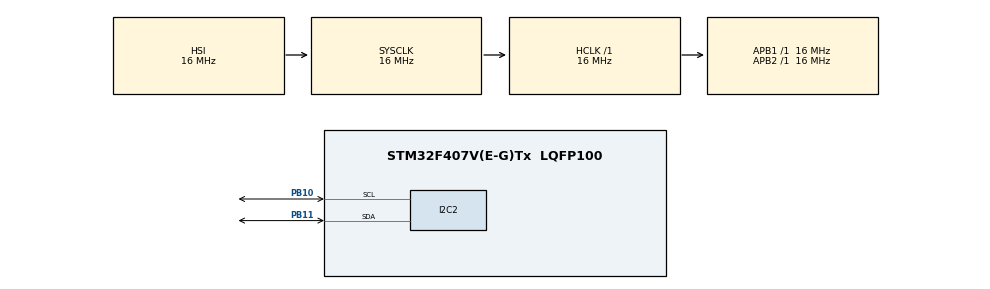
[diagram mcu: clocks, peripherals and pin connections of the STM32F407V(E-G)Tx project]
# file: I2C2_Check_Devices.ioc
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Mcu.Family=STM32F4
Mcu.Name=STM32F407V(E-G)Tx
Mcu.Package=LQFP100
NVIC.PriorityGroup=NVIC_PRIORITYGROUP_4
PB10.Mode=I2C
PB10.Signal=I2C2_SCL
PB11.Mode=I2C
PB11.Signal=I2C2_SDA
ProjectManager.HeapSize=0x200
ProjectManager.StackSize=0x400
ProjectManager.TargetToolchain=STM32CubeIDE
RCC.AHBFreq_Value=16000000
RCC.APB1Freq_Value=16000000
RCC.APB2Freq_Value=16000000
RCC.CortexFreq_Value=16000000
RCC.HSE_VALUE=25000000
RCC.HSI_VALUE=16000000
RCC.LSE_VALUE=32768
RCC.SYSCLKFreq_VALUE=16000000
RCC.VCOOutputFreq_Value=192000000
board=custom

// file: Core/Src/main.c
/* USER CODE BEGIN Header */
/**
 ******************************************************************************
 * @file           : main.c
 * @brief          : Main program body
 ******************************************************************************
 * @attention
 *
 * Copyright (c) 2026 STMicroelectronics.
 * All rights reserved.
 *
 * This software is licensed under terms that can be found in the LICENSE file
 * in the root directory of this software component.
 * If no LICENSE file comes with this software, it is provided AS-IS.
 *
 ******************************************************************************
 */
/* USER CODE END Header */
#include "main.h"

I2C_HandleTypeDef hi2c2;

/* USER CODE BEGIN PV */
uint8_t address[128] = { 0 };
uint8_t count = 0;

/* USER CODE END PV */

void SystemClock_Config(void);
static void MX_GPIO_Init(void);
static void MX_I2C2_Init(void);

/* USER CODE BEGIN 0 */

static void I2C_Bus_Recovery(GPIO_TypeDef *port, uint16_t scl_pin, uint16_t sda_pin)
{
    GPIO_InitTypeDef GPIO_InitStruct = {0};

    // SCL ve SDA'yı manuel open-drain GPIO çıkışı yap
    GPIO_InitStruct.Mode  = GPIO_MODE_OUTPUT_OD;
    GPIO_InitStruct.Pull  = GPIO_PULLUP;
    GPIO_InitStruct.Speed = GPIO_SPEED_FREQ_LOW;

    GPIO_InitStruct.Pin = scl_pin;
    HAL_GPIO_Init(port, &GPIO_InitStruct);
    GPIO_InitStruct.Pin = sda_pin;
    HAL_GPIO_Init(port, &GPIO_InitStruct);

    HAL_GPIO_WritePin(port, sda_pin, GPIO_PIN_SET);
    HAL_GPIO_WritePin(port, scl_pin, GPIO_PIN_SET);

    // SDA hâlâ LOW ise, slave'i serbest bırakmak için 9 clock darbesi gönder
    for (int i = 0; i < 9; i++)
    {
        if (HAL_GPIO_ReadPin(port, sda_pin) == GPIO_PIN_SET)
            break;

        HAL_GPIO_WritePin(port, scl_pin, GPIO_PIN_RESET);
        HAL_Delay(1);
        HAL_GPIO_WritePin(port, scl_pin, GPIO_PIN_SET);
        HAL_Delay(1);
    }

    // Manuel STOP condition: SDA LOW iken SCL HIGH, sonra SDA HIGH
    HAL_GPIO_WritePin(port, sda_pin, GPIO_PIN_RESET);
    HAL_Delay(1);
    HAL_GPIO_WritePin(port, scl_pin, GPIO_PIN_SET);
    HAL_Delay(1);
    HAL_GPIO_WritePin(port, sda_pin, GPIO_PIN_SET);
    HAL_Delay(1);
}

/* USER CODE END 0 */

int main(void)
{

  /* MCU Configuration--------------------------------------------------------*/

  /* Reset of all peripherals, Initializes the Flash interface and the Systick. */
  HAL_Init();

  /* Configure the system clock */
  SystemClock_Config();

  /* Initialize all configured peripherals */
  MX_GPIO_Init();
  I2C_Bus_Recovery(GPIOB, GPIO_PIN_10, GPIO_PIN_11);
  MX_I2C2_Init();

  /* Infinite loop */
	while (1) {

    /* USER CODE BEGIN 3 */

		uint8_t count = 0;

		for (uint8_t addr7 = 0x08; addr7 <= 0x77; addr7++)
		{
		    if (HAL_I2C_IsDeviceReady(&hi2c2, (uint16_t)(addr7 << 1), 2, 40) == HAL_OK)
		    {
		        address[count++] = addr7;
		    }
		    HAL_Delay(2);		}

		HAL_Delay(500);

	}
  /* USER CODE END 3 */
}

void SystemClock_Config(void)
{
  RCC_OscInitTypeDef RCC_OscInitStruct = {0};
  RCC_ClkInitTypeDef RCC_ClkInitStruct = {0};

  /** Configure the main internal regulator output voltage
  */
  __HAL_RCC_PWR_CLK_ENABLE();
  __HAL_PWR_VOLTAGESCALING_CONFIG(PWR_REGULATOR_VOLTAGE_SCALE1);

  /** Initializes the RCC Oscillators according to the specified parameters
  * in the RCC_OscInitTypeDef structure.
  */
  RCC_OscInitStruct.OscillatorType = RCC_OSCILLATORTYPE_HSI;
  RCC_OscInitStruct.HSIState = RCC_HSI_ON;
  RCC_OscInitStruct.HSICalibrationValue = RCC_HSICALIBRATION_DEFAULT;
  RCC_OscInitStruct.PLL.PLLState = RCC_PLL_NONE;
  if (HAL_RCC_OscConfig(&RCC_OscInitStruct) != HAL_OK)
  {
    Error_Handler();
  }

  /** Initializes the CPU, AHB and APB buses clocks
  */
  RCC_ClkInitStruct.ClockType = RCC_CLOCKTYPE_HCLK|RCC_CLOCKTYPE_SYSCLK
                              |RCC_CLOCKTYPE_PCLK1|RCC_CLOCKTYPE_PCLK2;
  RCC_ClkInitStruct.SYSCLKSource = RCC_SYSCLKSOURCE_HSI;
  RCC_ClkInitStruct.AHBCLKDivider = RCC_SYSCLK_DIV1;
  RCC_ClkInitStruct.APB1CLKDivider = RCC_HCLK_DIV1;
  RCC_ClkInitStruct.APB2CLKDivider = RCC_HCLK_DIV1;

  if (HAL_RCC_ClockConfig(&RCC_ClkInitStruct, FLASH_LATENCY_0) != HAL_OK)
  {
    Error_Handler();
  }
}

static void MX_I2C2_Init(void)
{

  hi2c2.Instance = I2C2;
  hi2c2.Init.ClockSpeed = 100000;
  hi2c2.Init.DutyCycle = I2C_DUTYCYCLE_2;
  hi2c2.Init.OwnAddress1 = 0;
  hi2c2.Init.AddressingMode = I2C_ADDRESSINGMODE_7BIT;
  hi2c2.Init.DualAddressMode = I2C_DUALADDRESS_DISABLE;
  hi2c2.Init.OwnAddress2 = 0;
  hi2c2.Init.GeneralCallMode = I2C_GENERALCALL_DISABLE;
  hi2c2.Init.NoStretchMode = I2C_NOSTRETCH_DISABLE;
  if (HAL_I2C_Init(&hi2c2) != HAL_OK)
  {
    Error_Handler();
  }

}

static void MX_GPIO_Init(void)
{

  /* GPIO Ports Clock Enable */
  __HAL_RCC_GPIOB_CLK_ENABLE();

}

void Error_Handler(void)
{
	__disable_irq();
	while (1) {
	}
}
